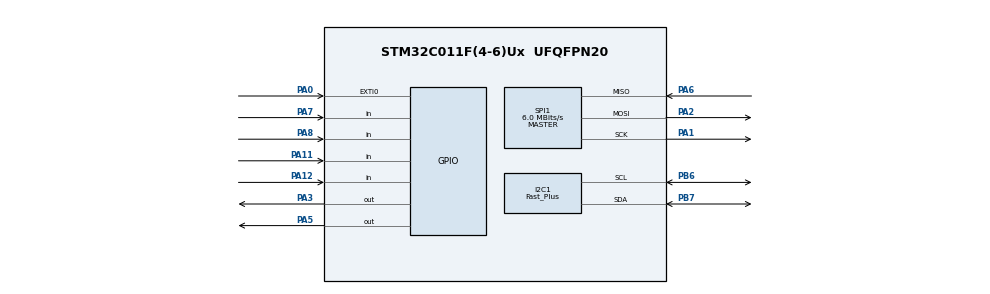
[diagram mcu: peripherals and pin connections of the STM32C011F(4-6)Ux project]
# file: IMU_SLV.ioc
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I2C1.I2C_Speed_Mode=I2C_Fast_Plus
I2C1.NoStretchMode=I2C_NOSTRETCH_DISABLE
I2C1.Timing=0x00100003
Mcu.Family=STM32C0
Mcu.Name=STM32C011F(4-6)Ux
Mcu.Package=UFQFPN20
NVIC.EXTI0_1_IRQn=true\:1\:0\:true\:true\:true\:2\:true\:true\:true
NVIC.I2C1_IRQn=true\:0\:0\:false\:true\:true\:1\:true\:true\:true
PA0.Signal=GPXTI0
PA1.Mode=Full_Duplex_Master
PA1.Signal=SPI1_SCK
PA11\ [PA9].GPIO_PuPd=GPIO_PULLDOWN
PA11\ [PA9].Signal=GPIO_Input
PA12\ [PA10].GPIO_PuPd=GPIO_PULLDOWN
PA12\ [PA10].Signal=GPIO_Input
PA13.Mode=Serial_Wire
PA13.Signal=DEBUG_SWDIO
PA14-BOOT0.Mode=Serial_Wire
PA14-BOOT0.Signal=DEBUG_SWCLK
PA2.Mode=Full_Duplex_Master
PA2.Signal=SPI1_MOSI
PA3.PinState=GPIO_PIN_SET
PA3.Signal=GPIO_Output
PA5.Signal=GPIO_Output
PA6.Mode=Full_Duplex_Master
PA6.Signal=SPI1_MISO
PA7.GPIO_PuPd=GPIO_PULLDOWN
PA7.Signal=GPIO_Input
PA8.GPIO_PuPd=GPIO_PULLDOWN
PA8.Signal=GPIO_Input
PB6.GPIO_Speed=GPIO_SPEED_FREQ_VERY_HIGH
PB6.Mode=I2C
PB6.Signal=I2C1_SCL
PB7.GPIO_Speed=GPIO_SPEED_FREQ_VERY_HIGH
PB7.Mode=I2C
PB7.Signal=I2C1_SDA
ProjectManager.HeapSize=0x200
ProjectManager.StackSize=0x400
ProjectManager.TargetToolchain=STM32CubeIDE
RCC.ADCFreq_Value=12000000
RCC.AHBFreq_Value=12000000
RCC.CortexFreq_Value=12000000
RCC.EXTERNAL_CLOCK_VALUE=12288000
RCC.HCLKFreq_Value=12000000
RCC.HSE_VALUE=8000000
RCC.HSI_VALUE=48000000
RCC.LSE_VALUE=32768
RCC.SYSCLKFreq_VALUE=12000000
SPI1.CLKPhase=SPI_PHASE_2EDGE
SPI1.CLKPolarity=SPI_POLARITY_HIGH
SPI1.CalculateBaudRate=6.0 MBits/s
SPI1.Direction=SPI_DIRECTION_2LINES
SPI1.Mode=SPI_MODE_MASTER
SPI1.VirtualType=VM_MASTER
board=custom

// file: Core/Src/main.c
/* USER CODE BEGIN Header */
/**
  ******************************************************************************
  * @file           : main.c
  * @brief          : Main program body
  ******************************************************************************
  * @attention
  *
  * Copyright (c) 2026 STMicroelectronics.
  * All rights reserved.
  *
  * This software is licensed under terms that can be found in the LICENSE file
  * in the root directory of this software component.
  * If no LICENSE file comes with this software, it is provided AS-IS.
  *
  ******************************************************************************
  */
/* USER CODE END Header */
#include "main.h"

/* USER CODE BEGIN Includes */
#include "imu_node.h"

/* USER CODE END Includes */

I2C_HandleTypeDef hi2c1;

SPI_HandleTypeDef hspi1;

void SystemClock_Config(void);
static void MX_GPIO_Init(void);
static void MX_SPI1_Init(void);
static void MX_I2C1_Init(void);
static void MX_NVIC_Init(void);

int main(void)
{

  /* MCU Configuration--------------------------------------------------------*/

  /* Reset of all peripherals, Initializes the Flash interface and the Systick. */
  HAL_Init();

  /* Configure the system clock */
  SystemClock_Config();

  /* Initialize all configured peripherals */
  MX_GPIO_Init();
  MX_SPI1_Init();
  MX_I2C1_Init();

  /* Initialize interrupts */
  //MX_NVIC_Init();
  /* USER CODE BEGIN 2 */
  uint8_t address = (uint8_t)HAL_GPIO_ReadPin(GPIOA, GPIO_PIN_7)
      + ((uint8_t)HAL_GPIO_ReadPin(GPIOA, GPIO_PIN_8) << 1)
      + ((uint8_t)HAL_GPIO_ReadPin(GPIOA, GPIO_PIN_11) << 2)
      + ((uint8_t)HAL_GPIO_ReadPin(GPIOA, GPIO_PIN_12) << 3);
  if (address < 1 || address > 12) Error_Handler();
  if (HAL_I2C_DeInit(&hi2c1) != HAL_OK) Error_Handler();
  hi2c1.Init.OwnAddress1 = address << 1;
  if (HAL_I2C_Init(&hi2c1) != HAL_OK) Error_Handler();
  imu_node_init(address);
  MX_NVIC_Init();
  if (HAL_I2C_EnableListen_IT(&hi2c1) != HAL_OK) Error_Handler();
  /* USER CODE END 2 */

  /* Infinite loop */
  /* USER CODE BEGIN WHILE */
  while (1)
  {
    imu_node_poll();
    /* USER CODE END WHILE */

  }
}

void SystemClock_Config(void)
{
  RCC_OscInitTypeDef RCC_OscInitStruct = {0};
  RCC_ClkInitTypeDef RCC_ClkInitStruct = {0};

  __HAL_FLASH_SET_LATENCY(FLASH_LATENCY_0);

  /** Initializes the RCC Oscillators according to the specified parameters
  * in the RCC_OscInitTypeDef structure.
  */
  RCC_OscInitStruct.OscillatorType = RCC_OSCILLATORTYPE_HSI;
  RCC_OscInitStruct.HSIState = RCC_HSI_ON;
  RCC_OscInitStruct.HSIDiv = RCC_HSI_DIV4;
  RCC_OscInitStruct.HSICalibrationValue = RCC_HSICALIBRATION_DEFAULT;
  if (HAL_RCC_OscConfig(&RCC_OscInitStruct) != HAL_OK)
  {
    Error_Handler();
  }

  /** Initializes the CPU, AHB and APB buses clocks
  */
  RCC_ClkInitStruct.ClockType = RCC_CLOCKTYPE_HCLK|RCC_CLOCKTYPE_SYSCLK
                              |RCC_CLOCKTYPE_PCLK1;
  RCC_ClkInitStruct.SYSCLKSource = RCC_SYSCLKSOURCE_HSI;
  RCC_ClkInitStruct.SYSCLKDivider = RCC_SYSCLK_DIV1;
  RCC_ClkInitStruct.AHBCLKDivider = RCC_HCLK_DIV1;
  RCC_ClkInitStruct.APB1CLKDivider = RCC_APB1_DIV1;

  if (HAL_RCC_ClockConfig(&RCC_ClkInitStruct, FLASH_LATENCY_0) != HAL_OK)
  {
    Error_Handler();
  }
}

/**
  * @brief NVIC Configuration.
  * @retval None
  */
static void MX_NVIC_Init(void)
{
  /* I2C1_IRQn interrupt configuration */
  HAL_NVIC_SetPriority(I2C1_IRQn, 0, 0);
  HAL_NVIC_EnableIRQ(I2C1_IRQn);
  /* EXTI0_1_IRQn interrupt configuration */
  HAL_NVIC_SetPriority(EXTI0_1_IRQn, 1, 0);
  HAL_NVIC_EnableIRQ(EXTI0_1_IRQn);
}

static void MX_I2C1_Init(void)
{

  hi2c1.Instance = I2C1;
  hi2c1.Init.Timing = 0x00100003;
  hi2c1.Init.OwnAddress1 = 0;
  hi2c1.Init.AddressingMode = I2C_ADDRESSINGMODE_7BIT;
  hi2c1.Init.DualAddressMode = I2C_DUALADDRESS_DISABLE;
  hi2c1.Init.OwnAddress2 = 0;
  hi2c1.Init.OwnAddress2Masks = I2C_OA2_NOMASK;
  hi2c1.Init.GeneralCallMode = I2C_GENERALCALL_DISABLE;
  hi2c1.Init.NoStretchMode = I2C_NOSTRETCH_DISABLE;
  if (HAL_I2C_Init(&hi2c1) != HAL_OK)
  {
    Error_Handler();
  }

  /** Configure Analogue filter
  */
  if (HAL_I2CEx_ConfigAnalogFilter(&hi2c1, I2C_ANALOGFILTER_ENABLE) != HAL_OK)
  {
    Error_Handler();
  }

  /** Configure Digital filter
  */
  if (HAL_I2CEx_ConfigDigitalFilter(&hi2c1, 0) != HAL_OK)
  {
    Error_Handler();
  }

  /** I2C Fast mode Plus enable
  */
  HAL_I2CEx_EnableFastModePlus(I2C_FASTMODEPLUS_I2C1);

}

static void MX_SPI1_Init(void)
{

  /* SPI1 parameter configuration*/
  hspi1.Instance = SPI1;
  hspi1.Init.Mode = SPI_MODE_MASTER;
  hspi1.Init.Direction = SPI_DIRECTION_2LINES;
  hspi1.Init.DataSize = SPI_DATASIZE_8BIT;
  hspi1.Init.CLKPolarity = SPI_POLARITY_HIGH;
  hspi1.Init.CLKPhase = SPI_PHASE_2EDGE;
  hspi1.Init.NSS = SPI_NSS_SOFT;
  hspi1.Init.BaudRatePrescaler = SPI_BAUDRATEPRESCALER_2;
  hspi1.Init.FirstBit = SPI_FIRSTBIT_MSB;
  hspi1.Init.TIMode = SPI_TIMODE_DISABLE;
  hspi1.Init.CRCCalculation = SPI_CRCCALCULATION_DISABLE;
  hspi1.Init.CRCPolynomial = 7;
  hspi1.Init.CRCLength = SPI_CRC_LENGTH_DATASIZE;
  hspi1.Init.NSSPMode = SPI_NSS_PULSE_DISABLE;
  if (HAL_SPI_Init(&hspi1) != HAL_OK)
  {
    Error_Handler();
  }

}

static void MX_GPIO_Init(void)
{
  GPIO_InitTypeDef GPIO_InitStruct = {0};

  /* GPIO Ports Clock Enable */
  __HAL_RCC_GPIOA_CLK_ENABLE();
  __HAL_RCC_GPIOB_CLK_ENABLE();

  /*Configure GPIO pin Output Level */
  HAL_GPIO_WritePin(GPIOA, GPIO_PIN_3, GPIO_PIN_SET);

  /*Configure GPIO pin Output Level */
  HAL_GPIO_WritePin(GPIOA, GPIO_PIN_5, GPIO_PIN_RESET);

  /*Configure GPIO pin : PA0 */
  GPIO_InitStruct.Pin = GPIO_PIN_0;
  GPIO_InitStruct.Mode = GPIO_MODE_IT_RISING;
  GPIO_InitStruct.Pull = GPIO_NOPULL;
  HAL_GPIO_Init(GPIOA, &GPIO_InitStruct);

  /*Configure GPIO pins : PA3 PA5 */
  GPIO_InitStruct.Pin = GPIO_PIN_3|GPIO_PIN_5;
  GPIO_InitStruct.Mode = GPIO_MODE_OUTPUT_PP;
  GPIO_InitStruct.Pull = GPIO_NOPULL;
  GPIO_InitStruct.Speed = GPIO_SPEED_FREQ_LOW;
  HAL_GPIO_Init(GPIOA, &GPIO_InitStruct);

  /*Configure GPIO pins : PA7 PA8 PA11 PA12 */
  GPIO_InitStruct.Pin = GPIO_PIN_7|GPIO_PIN_8|GPIO_PIN_11|GPIO_PIN_12;
  GPIO_InitStruct.Mode = GPIO_MODE_INPUT;
  GPIO_InitStruct.Pull = GPIO_PULLDOWN;
  HAL_GPIO_Init(GPIOA, &GPIO_InitStruct);

}

void Error_Handler(void)
{
  __disable_irq();
  while (1)
  {
  }
}
